VERSION ""

NS_ :

BS_:

BU_: DBG MASTER GEO SENSOR MOTORIO BRIDGE

BO_ 100 STOP_CAR: 1 MASTER
 SG_ STOP_CAR_data : 0|8@1+ (1,0) [0|0] "" BRIDGE,GEO,SENSOR,MOTORIO,DBG

BO_ 110 RESET: 1 MASTER
 SG_ RESET_data : 0|8@1+ (1,0) [0|0] "" BRIDGE,GEO,SENSOR,MOTORIO,DBG

BO_ 120 POWER_SYNC_ACK: 1 MASTER
 SG_ POWER_SYNC_ACK_data : 0|8@1+ (1,0) [0|0] "" BRIDGE,GEO,SENSOR,MOTORIO,DBG

BO_ 130 STOP_CMD_APP: 1 BRIDGE
 SG_ STOP_CMD_APP_data : 0|8@1+ (1,0) [0|0] "" MASTER,DBG

BO_ 140 START_CMD_APP: 1 BRIDGE
 SG_ START_CMD_APP_data : 0|8@1+ (1,0) [0|0] "" MASTER,DBG

BO_ 200 MOTOR_POWER_SYNC: 1 MOTORIO
 SG_ MOTOR_POWER_SYNC_data : 0|8@1+ (1,0) [0|0] "" MASTER,DBG

BO_ 210 SENSOR_POWER_SYNC: 1 SENSOR
 SG_ SENSOR_POWER_SYNC_data : 0|8@1+ (1,0) [0|0] "" MASTER,DBG

BO_ 220 BRIDGE_POWER_SYNC: 1 BRIDGE
 SG_ GEO_POWER_SYNC_data : 0|8@1+ (1,0) [0|0] "" MASTER,DBG

BO_ 230 GEO_POWER_SYNC: 1 GEO
 SG_ BRIDGE_POWER_SYNC_data : 0|8@1+ (1,0) [0|0] "" MASTER,DBG

BO_ 300 MOTORIO_HEARTBEAT: 1 MOTORIO
 SG_ MOTORIO_HEARTBEAT_data : 0|8@1+ (1,0) [0|0] "" MASTER,DBG

BO_ 310 SENSOR_HEARTBEAT: 1 SENSOR
 SG_ SENSOR_HEARTBEAT_data : 0|8@1+ (1,0) [0|0] "" MASTER,DBG

BO_ 320 BRIDGE_HEARTBEAT: 1 BRIDGE
 SG_ BRIDGE_HEARTBEAT_data : 0|8@1+ (1,0) [0|0] "" MASTER,DBG

BO_ 330 GEO_HEARTBEAT: 1 GEO
 SG_ GEO_HEARTBEAT_data : 0|8@1+ (1,0) [0|0] "" MASTER,DBG

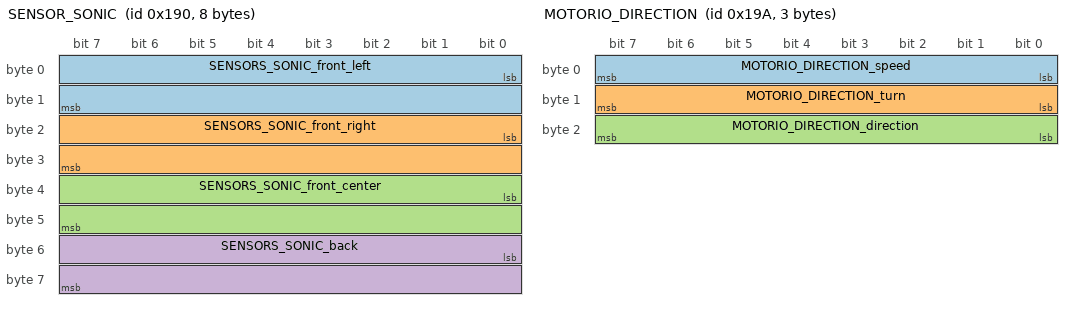
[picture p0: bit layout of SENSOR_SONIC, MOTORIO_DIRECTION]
BO_ 400 SENSOR_SONIC: 8 SENSOR
 SG_ SENSORS_SONIC_front_left : 0|16@1+ (1,0) [0|0] "" MASTER,MOTORIO,DBG
 SG_ SENSORS_SONIC_front_right : 16|16@1+ (1,0) [0|0] "" MASTER,MOTORIO,DBG
 SG_ SENSORS_SONIC_front_center : 32|16@1+ (1,0) [0|0] "" MASTER,MOTORIO,DBG
 SG_ SENSORS_SONIC_back : 48|16@1+ (1,0) [0|0] "" MASTER,MOTORIO,DBG

BO_ 410 MOTORIO_DIRECTION: 3 MASTER
 SG_ MOTORIO_DIRECTION_speed : 0|8@1+ (1,0) [0|10] "" MOTORIO,DBG
 SG_ MOTORIO_DIRECTION_turn : 8|8@1+ (1,-4) [-3|3] "" MOTORIO,DBG
 SG_ MOTORIO_DIRECTION_direction : 16|8@1+ (1,0) [0|2] "" MOTORIO,DBG

BO_ 420 BRIDGE_TOTAL_CHECKPOINT: 1 BRIDGE
 SG_ BRIDGE_TOTAL_CHECKPOINT_NUMBER : 0|8@1+ (1,0) [0|0] "" MASTER,MOTORIO,DBG

BO_ 430 RECEIVE_START_ACK: 1 MASTER
 SG_ RECEIVE_START_ACK_ack : 0|8@1+ (0,0) [0|0] "" BRIDGE,DBG

BO_ 440 BLUETOOTH_DATA: 8 BRIDGE
 SG_ BLUETOOTH_DATA_LAT : 0|32@1+ (0.000001,0) [0|0] "" MASTER,DBG
 SG_ BLUETOOTH_DATA_LON : 32|32@1+ (0.000001,0) [0|0] "" MASTER,DBG

BO_ 450 NEXT_CHECKPOINT_DATA: 8 MASTER
 SG_ NEXT_CHECKPOINT_DATA_latitude : 0|32@1+ (0.000001,0) [0|0] "" GEO,DBG
 SG_ NEXT_CHECKPOINT_DATA_longitude : 32|32@1+ (0.000001,0) [0|0] "" GEO,DBG

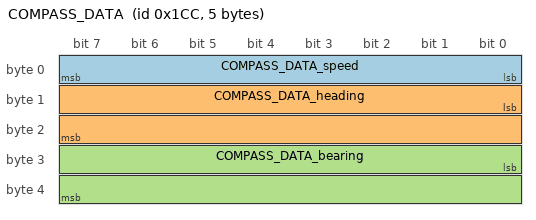
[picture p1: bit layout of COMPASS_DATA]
BO_ 460 COMPASS_DATA: 5 GEO
 SG_ COMPASS_DATA_speed : 0|8@1+ (1,0) [0|0] "" MASTER,DBG
 SG_ COMPASS_DATA_heading : 8|16@1+ (1,0) [0|0] "" MASTER,DBG
 SG_ COMPASS_DATA_bearing : 24|16@1+ (1,0) [0|0] "" MASTER,DBG

BO_ 470 CURRENT_LOCATION_ACK: 1 BRIDGE
 SG_ CURRENT_LOCATION_ACK_ack : 0|8@1+ (1,0) [0|0] "" MASTER,GEO,DBG

BO_ 480 GPS_LOCATION: 8 GEO
 SG_ GPS_LOCATION_latitude : 0|32@1+ (0.000001,0) [0|0] "" MASTER,BRIDGE,DBG
 SG_ GPS_LOCATION_longitude : 32|32@1+ (0.000001,0) [0|0] "" MASTER,BRIDGE,DBG

BO_ 490 DISTANCE_TO_DESTINATION: 1 GEO
 SG_ DISTANCE_TO_DESTINATION_data : 0|8@1+ (0,0) [0|0] "" MASTER, MOTORIO,DBG

BO_ 500 BATTERY_STATUS: 1 SENSOR
 SG_ DISTANCE_TO_DESTINATION_status : 0|8@1+ (0,0) [0|0] "" MASTER, MOTORIO,DBG

CM_ BU_ DBG "Debug node used to determine whether the message is received by any other node";
CM_ BU_ DRIVER "Master Controller";
CM_ BU_ SENSOR "Sensor Controller";
CM_ BU_ MOTORIO "Motor I/O controller";
CM_ BU_ BRIDGE "BRIDGE Controller";
CM_ BU_ GEO "Geo Controller";
CM_ BO_ 2 "Sync message used to synchronize the controllers";

BA_DEF_ "BusType" STRING ;
BA_DEF_ BO_ "GenMsgCycleTime" INT 0 0;

BA_DEF_DEF_ "BusType" "CAN";
BA_DEF_DEF_ "GenMsgCycleTime" 0;

BA_ "GenMsgCycleTime" BO_ 300	          1;
BA_ "GenMsgCycleTime" BO_ 310	          1;
BA_ "GenMsgCycleTime" BO_ 320	          1;
BA_ "GenMsgCycleTime" BO_ 330             1;
BA_ "GenMsgCycleTime" BO_ 400 	          10;
BA_ "GenMsgCycleTime" BO_ 410             10;
BA_ "GenMsgCycleTime" BO_ 450             10;
BA_ "GenMsgCycleTime" BO_ 460             10;
BA_ "GenMsgCycleTime" BO_ 470             10;
BA_ "GenMsgCycleTime" BO_ 480             10;
